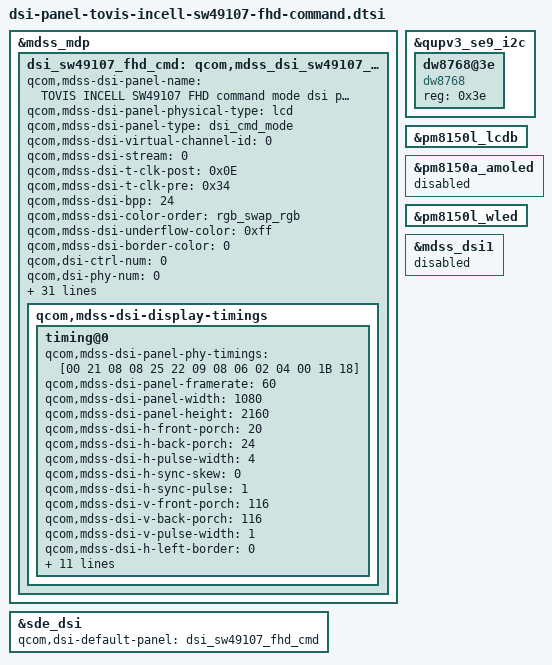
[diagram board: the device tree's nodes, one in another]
/* Copyright (c) 2014, Code Aurora Forum. All rights reserved.
 *
 * This program is free software; you can redistribute it and/or modify
 * it under the terms of the GNU General Public License version 2 and
 * only version 2 as published by the Free Software Foundation.
 *
 * This program is distributed in the hope that it will be useful,
 * but WITHOUT ANY WARRANTY; without even the implied warranty of
 * MERCHANTABILITY or FITNESS FOR A PARTICULAR PURPOSE.  See the
 * GNU General Public License for more details.
 */

&mdss_mdp {
	dsi_sw49107_fhd_cmd: qcom,mdss_dsi_sw49107_fhd_cmd{
		//qcom,cont-splash-enabled;
		qcom,mdss-dsi-panel-name = "TOVIS INCELL SW49107 FHD command mode dsi panel";
		//qcom,mdss-dsi-panel-controller = <&mdss_dsi0>;
		qcom,mdss-dsi-panel-physical-type = "lcd";
		qcom,mdss-dsi-panel-type = "dsi_cmd_mode";
		//qcom,mdss-dsi-panel-destination = "display_1";
		qcom,mdss-dsi-virtual-channel-id = <0>;
		qcom,mdss-dsi-stream = <0>;
		qcom,mdss-dsi-t-clk-post = <0x0E>;
		qcom,mdss-dsi-t-clk-pre = <0x34>;
		qcom,mdss-dsi-bpp = <24>;
		qcom,mdss-dsi-color-order = "rgb_swap_rgb";
		qcom,mdss-dsi-underflow-color = <0xff>;
		qcom,mdss-dsi-border-color = <0>;
		qcom,dsi-ctrl-num = <0>;
		qcom,dsi-phy-num = <0>;
		qcom,dsi-select-clocks = "mux_byte_clk0", "mux_pixel_clk0",
								"src_byte_clk0", "src_pixel_clk0",
								"shadow_byte_clk0", "shadow_pixel_clk0";
		//qcom,esd-check-enabled;
		qcom,mdss-dsi-traffic-mode = "non_burst_sync_pulse";
		qcom,mdss-dsi-lane-map = "lane_map_0123";
		qcom,mdss-dsi-dma-trigger = "trigger_sw";
		qcom,mdss-dsi-mdp-trigger = "none";
		qcom,mdss-dsi-bllp-eof-power-mode;
		qcom,mdss-dsi-bllp-power-mode;
		//qcom,ulps-enabled;
		//qcom,suspend-ulps-enabled;
		qcom,mdss-dsi-lane-0-state;
		qcom,mdss-dsi-lane-1-state;
		qcom,mdss-dsi-lane-2-state;
		qcom,mdss-dsi-lane-3-state;
		qcom,mdss-dsi-tx-eot-append;

		qcom,mdss-dsi-bl-min-level = <1>;
		qcom,mdss-dsi-bl-max-level = <2047>;
		qcom,mdss-dsi-bl-pmic-control-type = "bl_ctrl_wled";
		qcom,mdss-dsi-reset-sequence = <0 1>, <1 1>;

		lge,mdss-dsi-lp11-off;

		qcom,mdss-dsi-te-pin-select = <1>;
		qcom,mdss-dsi-te-dcs-command = <1>;
		//qcom,mdss-dsi-te-check-enable;
		//qcom,mdss-dsi-te-using-te-pin;
		//qcom,mdss-dsi-lp11-init;
		qcom,mdss-dsi-wr-mem-start = <0x2c>;
		qcom,mdss-dsi-wr-mem-continue = <0x3c>;

		qcom,mdss-pan-physical-width-dimension = <70>;
		qcom,mdss-pan-physical-height-dimension = <140>;

		lge,blmap-size = <256>;
		lge,blmap = <
			0 16 32 48 64 80 96 112 128 145 161 177 193 209 225
			241 257 273 289 305 321 337 353 369 385 401 418 434 450 466
			482 498 514 530 546 562 578 594 610 626 642 658 674 691 707
			723 739 755 771 787 803 819 835 851 867 883 899 915 931 947
			964 980 996 1012 1028 1044 1060 1076 1092 1108 1124 1140 1156 1172 1188
			1204 1220 1237 1253 1269 1285 1301 1317 1333 1349 1365 1381 1397 1413 1429
			1445 1461 1477 1493 1510 1526 1542 1558 1574 1590 1606 1622 1638 1654 1670
			1686 1702 1718 1734 1750 1766 1783 1799 1815 1831 1847 1863 1879 1895 1911
			1927 1943 1959 1975 1991 2007 2023 2039 2056 2072 2088 2104 2120 2136 2152
			2168 2184 2200 2216 2232 2248 2264 2280 2296 2312 2329 2345 2361 2377 2393
			2409 2425 2441 2457 2473 2489 2505 2521 2537 2553 2569 2585 2602 2618 2634
			2650 2666 2682 2698 2714 2730 2746 2762 2778 2794 2810 2826 2842 2858 2875
			2891 2907 2923 2939 2955 2971 2987 3003 3019 3035 3051 3067 3083 3099 3115
			3131 3148 3164 3180 3196 3212 3228 3244 3260 3276 3292 3308 3324 3340 3356
			3372 3388 3404 3421 3437 3453 3469 3485 3501 3517 3533 3549 3565 3581 3597
			3613 3629 3645 3661 3677 3694 3710 3726 3742 3758 3774 3790 3806 3822 3838
			3854 3870 3886 3902 3918 3934 3950 3967 3983 3999 4015 4031 4047 4063 4079
			4095
		>;

		qcom,mdss-dsi-display-timings {
			timing@0{
				qcom,mdss-dsi-panel-phy-timings = [00 21 08 08 25 22 09 08 06 02 04 00 1B 18];
				qcom,mdss-dsi-panel-framerate = <60>;
				qcom,mdss-dsi-panel-width = <1080>;
				qcom,mdss-dsi-panel-height = <2160>;
				qcom,mdss-dsi-h-front-porch = <20>;
				qcom,mdss-dsi-h-back-porch = <24>;
				qcom,mdss-dsi-h-pulse-width = <4>;
				qcom,mdss-dsi-h-sync-skew = <0>;
				qcom,mdss-dsi-h-sync-pulse = <1>;
				qcom,mdss-dsi-v-front-porch = <116>;
				qcom,mdss-dsi-v-back-porch = <116>;
				qcom,mdss-dsi-v-pulse-width = <1>;
				qcom,mdss-dsi-h-left-border = <0>;
				qcom,mdss-dsi-h-right-border = <0>;
				qcom,mdss-dsi-v-top-border = <0>;
				qcom,mdss-dsi-v-bottom-border = <0>;
				qcom,display-topology = <1 0 1>;
				qcom,default-topology-index = <0>;

				qcom,mdss-dsi-on-command = [
					39 01 00 00 00 00 05 // Page Address Set
					2B 00 00 08 6F

					15 01 00 00 00 00 02 // Memory Access Control
					36 00

					39 01 00 00 00 00 03 // Tear scan line
					44 05 DC

					15 01 00 00 00 00 02 // Manufacturer Command Protection
					B0 AC

					39 01 00 00 00 00 06 // MIPI DSI Configuration
					B1 36 00 80 14 85

					39 01 00 00 00 00 04 // MIPI D-PHY Configuration
					B2 77 04 4C

					39 01 00 00 00 00 09 // Display Control 1
					B3 02 04 0A 00 5C 00 02 12

					39 01 00 00 00 00 12 // Display Control 2
					B4 0A 02 78 05 05 E0 01 00 00 00 00 00 00 00 00 22 96

					39 01 00 00 00 00 13 // Display Control 3
					B5 02 0D 03 01 13 00 00 00 00 00 00 60 05 10 10 10 10 00

					39 01 00 00 00 00 08 // Display Control 4
					B6 00 28 14 5B 04 B6 08

					39 01 00 00 00 00 07 // Panel Setting
					B7 08 50 1B 02 10 8C

					39 01 00 00 00 00 20 // Touch Timing Control
					B8 07 3C 90 44 A6 00 05 00 00 10 04 04 01 40 01 45 1C C2 21 00 00 10 01 01 01 64 00 58 00 00 00

					39 01 00 00 00 00 06 // Touch Source Setting
					B9 32 32 2A 37 03

					39 01 00 00 00 00 07 // Power Control 3
					C3 05 06 06 50 66 1B

					39 01 00 00 00 00 05 // Power Control 4
					C4 A2 AE 90 00

					39 01 00 00 00 00 06 // Power Control 5
					C5 94 44 6C 33 33

					39 01 00 00 00 00 03 // Vcom setting
					C6 12 01

					39 01 00 00 00 00 07 // Power Sequence Option Configuration
					CA 05 0D 00 34 0A FF

					39 01 00 00 00 00 05 // Abrupt Power Off Control
					CB 3F 1B B0 A0

					39 01 00 00 00 00 07 // LFD Control
					CC F3 F0 55 3D 3D 11

					39 01 00 00 00 00 08 // Tail TFT Setting
					CD 11 50 50 90 00 F3 A0

					39 01 00 00 00 00 07 // Touch power control
					CE 48 48 2E 10 00 AB

					39 01 00 00 00 00 7F // Gamma Curve 0
					D0 01 01 02 02 10 10 19 19 2E
					2E 3A 3A 5B 5B 7A 7A 8E 8E 9E
					9E 6E 6E C3 C3 B1 B1 9B 9B 79
					79 53 53 44 44 37 37 21 21 12
					12 00 00 01 01 02 02 10	10 19
					19 2E 2E 3A 3A 5D 5D 7A 7A 8F
					8F 9F 9F 6D 6D C3 C3 B1 B1 9B
					9B 7B 7B 55 55 46 46 3A 3A 24
					24 14 14 00 00 01 01 02 02 10
					10 19 19 2E 2E 3A 3A 5B 5B 77
					77 8C 8C 9C 9C 6C 6C C4	C4 B3
					B3 9D 9D 7D 7D 58 58 48 48 3C
					3C 25 25 14 14 00 00

					39 01 00 00 00 00 04 // Sensor setting
					DE 00 44 03

					39 01 00 00 00 00 0D // Left Side GIP Pad Setting
					E5 0E 11 0B 0A 50 06 02 25 0C 25 25 25

					39 01 00 00 00 00 0D // Right Side GIP Pad Setting
					E6 0E 11 0B 0A 50 09 05 25 0C 25 25 25

					39 01 00 00 00 00 0D // Left Side MUX Pad Setting
					E7 58 56 54 57 55 53 18 16 14 17 15 13

					39 01 00 00 00 00 0D // Right Side MUX Pad Setting
					E8 58 56 54 57 55 53 18 16 14 17 15 13

					39 01 00 00 32 00 06 // ESD Auto Recover Setting
					ED 80 00 01 56 08

					15 01 00 00 00 00 02 // Write display brightness
					51 FF

					15 01 00 00 00 00 02 // Write control display
					53 2C

					15 01 00 00 00 00 02 // Image Enhancement
					55 81

					15 01 00 00 00 00 02 // Write cabc min brightness
					5E 00

					39 01 00 00 00 00 18 // CABC ctrl1
					F9 1F 3F 5F 7F
					A0 CF E7 12 1D
					20 20 1B 13 0E
					09 B4 C0 CD DA
					E8 F0 F7 FF

					39 01 00 00 00 00 0F // CABC ctrl2
					FA FF 22 22 22
					20 00 70 22 02
					60 08 70 42 1C

					05 01 00 00 64 00 01 // Sleep out
					11

					15 01 00 00 00 00 02 // TE on
					35 00

					05 01 00 00 0A 00 01 // Display on
					29
				];
				qcom,mdss-dsi-on-command-state = "dsi_lp_mode";

				qcom,mdss-dsi-off-command = [
					05 01 00 00 00 00 01 // Display off
					28

					05 01 00 00 8C 00 01 // Sleep in
					10
				];
				qcom,mdss-dsi-off-command-state = "dsi_hs_mode";


			};
		};
	};
};

&sde_dsi  {
	qcom,dsi-default-panel = <&dsi_sw49107_fhd_cmd>;
};

/* SE 9 pin mappings for DW8768 */
&qupv3_se9_i2c {
	dw8768@3e {
		compatible = "dw8768";
		status="okay";
		reg = <0x3e>;
	};
};

&pm8150l_lcdb {
    status = "ok";
};

&pm8150a_amoled {
    status = "disabled";
};

&pm8150l_wled {
    status = "ok";
};

&mdss_dsi1 {
	status = "disabled";
};
